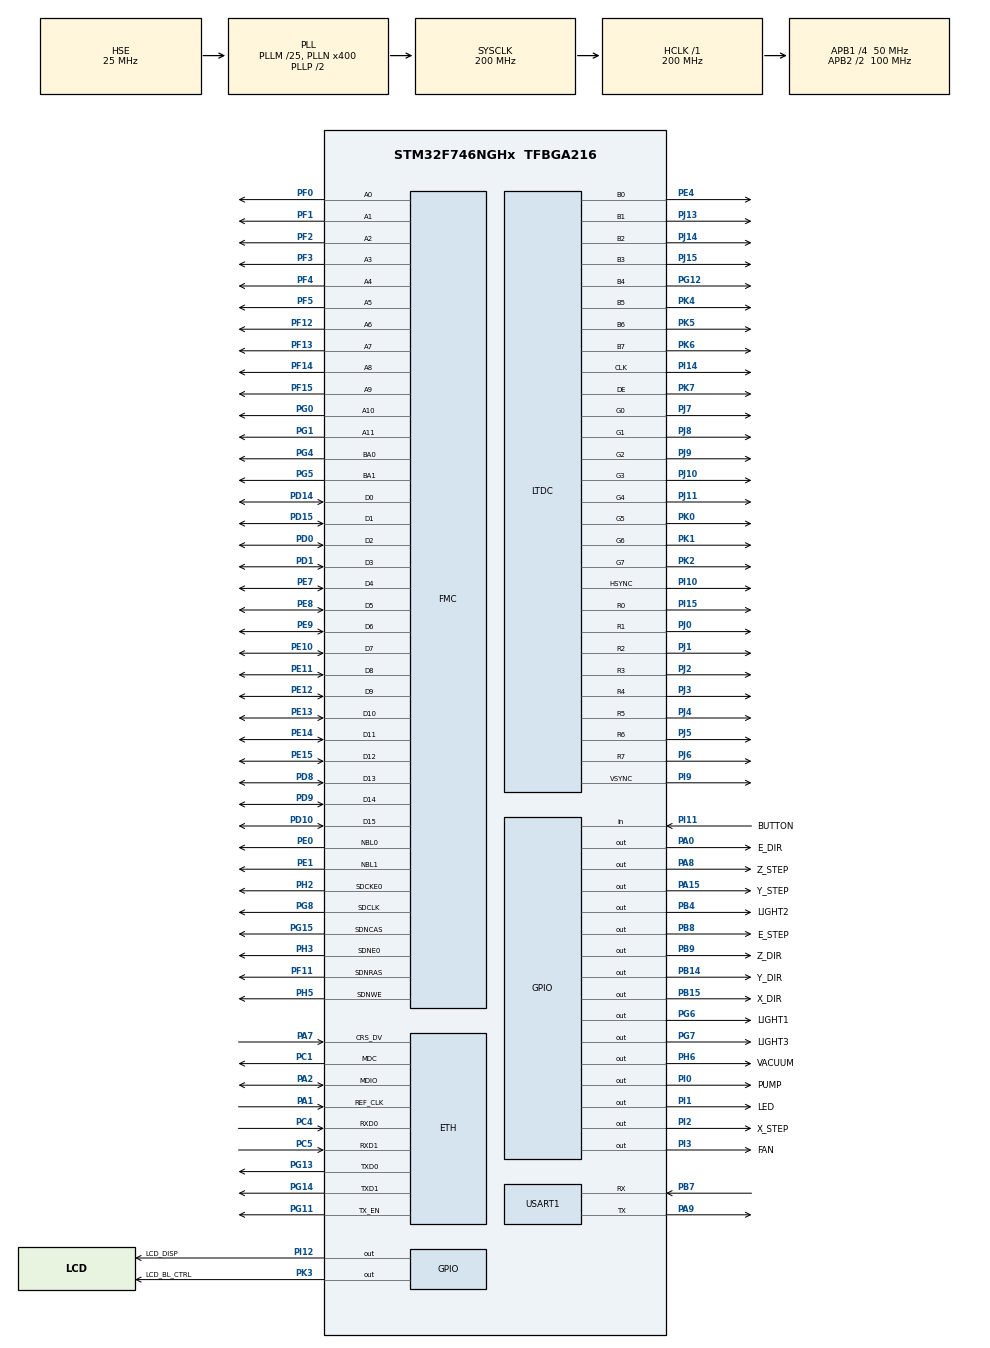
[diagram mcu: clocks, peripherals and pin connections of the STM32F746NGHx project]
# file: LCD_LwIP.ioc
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ETH.MACAddr=00\:80\:E1\:00\:00\:44
ETH.MediaInterface=ETH_MEDIA_INTERFACE_RMII
ETH.PhyAddress=0
LTDC.ActiveH=272
LTDC.ActiveW=480
LTDC.Alpha_L0=255
LTDC.Alpha_L1=255
LTDC.BlendingFactor1_L0=LTDC_BLENDING_FACTOR1_PAxCA
LTDC.BlendingFactor1_L1=LTDC_BLENDING_FACTOR1_PAxCA
LTDC.BlendingFactor2_L0=LTDC_BLENDING_FACTOR2_PAxCA
LTDC.BlendingFactor2_L1=LTDC_BLENDING_FACTOR2_PAxCA
LTDC.Green=255
LTDC.HBP=13
LTDC.HFP=32
LTDC.HSync=41
LTDC.ImageHeight_L0=272
LTDC.ImageHeight_L1=272
LTDC.ImageWidth_L0=480
LTDC.ImageWidth_L1=480
LTDC.PixelFormat_L0=LTDC_PIXEL_FORMAT_ARGB1555
LTDC.PixelFormat_L1=LTDC_PIXEL_FORMAT_ARGB1555
LTDC.VSync=10
LTDC.WindowX1_L0=480
LTDC.WindowX1_L1=480
LTDC.WindowY1_L0=272
LTDC.WindowY1_L1=272
LWIP.IP_ADDRESS=192.168.001.069
LWIP.LWIP_DHCP=0
LWIP.NETMASK_ADDRESS=255.255.255.000
LWIP.Version=v2.1.2_Cube
Mcu.Family=STM32F7
Mcu.Name=STM32F746NGHx
Mcu.Package=TFBGA216
NVIC.PriorityGroup=NVIC_PRIORITYGROUP_4
NVIC.TIM2_IRQn=true\:0\:0\:false\:false\:true\:true\:true
NVIC.TIM4_IRQn=true\:0\:0\:false\:false\:true\:true\:true
PA0/WKUP.GPIO_Label=E_DIR
PA0/WKUP.Signal=GPIO_Output
PA1.Mode=RMII
PA1.Signal=ETH_REF_CLK
PA15.GPIO_Label=Y_STEP
PA15.Signal=GPIO_Output
PA2.Mode=RMII
PA2.Signal=ETH_MDIO
PA7.Mode=RMII
PA7.Signal=ETH_CRS_DV
PA8.GPIO_Label=Z_STEP
PA8.Signal=GPIO_Output
PA9.Mode=Asynchronous
PA9.Signal=USART1_TX
PB14.GPIO_Label=Y_DIR
PB14.Signal=GPIO_Output
PB15.GPIO_Label=X_DIR
PB15.Signal=GPIO_Output
PB4.GPIO_Label=LIGHT2
PB4.Signal=GPIO_Output
PB7.Mode=Asynchronous
PB7.Signal=USART1_RX
PB8.GPIO_Label=E_STEP
PB8.Signal=GPIO_Output
PB9.GPIO_Label=Z_DIR
PB9.Signal=GPIO_Output
PC1.Mode=RMII
PC1.Signal=ETH_MDC
PC14/OSC32_IN.Mode=LSE-External-Oscillator
PC14/OSC32_IN.Signal=RCC_OSC32_IN
PC15/OSC32_OUT.Mode=LSE-External-Oscillator
PC15/OSC32_OUT.Signal=RCC_OSC32_OUT
PC4.Mode=RMII
PC4.Signal=ETH_RXD0
PC5.Mode=RMII
PC5.Signal=ETH_RXD1
PD0.Signal=FMC_D2_DA2
PD1.Signal=FMC_D3_DA3
PD10.Signal=FMC_D15_DA15
PD14.Signal=FMC_D0_DA0
PD15.Signal=FMC_D1_DA1
PD8.Signal=FMC_D13_DA13
PD9.Signal=FMC_D14_DA14
PE0.Signal=FMC_NBL0
PE1.Signal=FMC_NBL1
PE10.Signal=FMC_D7_DA7
PE11.Signal=FMC_D8_DA8
PE12.Signal=FMC_D9_DA9
PE13.Signal=FMC_D10_DA10
PE14.Signal=FMC_D11_DA11
PE15.Signal=FMC_D12_DA12
PE4.Mode=RGB888
PE4.Signal=LTDC_B0
PE7.Signal=FMC_D4_DA4
PE8.Signal=FMC_D5_DA5
PE9.Signal=FMC_D6_DA6
PF0.Signal=FMC_A0
PF1.Signal=FMC_A1
PF11.Signal=FMC_SDNRAS
PF12.Signal=FMC_A6
PF13.Signal=FMC_A7
PF14.Signal=FMC_A8
PF15.Signal=FMC_A9
PF2.Signal=FMC_A2
PF3.Signal=FMC_A3
PF4.Signal=FMC_A4
PF5.Signal=FMC_A5
PG0.Signal=FMC_A10
PG1.Signal=FMC_A11
PG11.Mode=RMII
PG11.Signal=ETH_TX_EN
PG12.Mode=RGB888
PG12.Signal=LTDC_B4
PG13.Mode=RMII
PG13.Signal=ETH_TXD0
PG14.Mode=RMII
PG14.Signal=ETH_TXD1
PG15.Signal=FMC_SDNCAS
PG4.Signal=FMC_A14_BA0
PG5.Signal=FMC_A15_BA1
PG6.GPIO_Label=LIGHT1
PG6.Signal=GPIO_Output
PG7.GPIO_Label=LIGHT3
PG7.Signal=GPIO_Output
PG8.Signal=FMC_SDCLK
PH0/OSC_IN.Mode=HSE-External-Oscillator
PH0/OSC_IN.Signal=RCC_OSC_IN
PH1/OSC_OUT.Mode=HSE-External-Oscillator
PH1/OSC_OUT.Signal=RCC_OSC_OUT
PH2.Mode=SdramChipSelect1_1
PH2.Signal=FMC_SDCKE0
PH3.Mode=SdramChipSelect1_1
PH3.Signal=FMC_SDNE0
PH5.Signal=FMC_SDNWE
PH6.GPIO_Label=VACUUM
PH6.Signal=GPIO_Output
PI0.GPIO_Label=PUMP
PI0.Signal=GPIO_Output
PI1.GPIO_Label=LED
PI1.Signal=GPIO_Output
PI10.Mode=RGB888
PI10.Signal=LTDC_HSYNC
PI11.GPIO_Label=BUTTON
PI11.Signal=GPIO_Input
PI12.GPIO_Label=LCD_DISP
PI12.Signal=GPIO_Output
PI14.Mode=RGB888
PI14.Signal=LTDC_CLK
PI15.Mode=RGB888
PI15.Signal=LTDC_R0
PI2.GPIO_Label=X_STEP
PI2.Signal=GPIO_Output
PI3.GPIO_Label=FAN
PI3.Signal=GPIO_Output
PI9.Mode=RGB888
PI9.Signal=LTDC_VSYNC
PJ0.Mode=RGB888
PJ0.Signal=LTDC_R1
PJ1.Mode=RGB888
PJ1.Signal=LTDC_R2
PJ10.Mode=RGB888
PJ10.Signal=LTDC_G3
PJ11.Mode=RGB888
PJ11.Signal=LTDC_G4
PJ13.Mode=RGB888
PJ13.Signal=LTDC_B1
PJ14.Mode=RGB888
PJ14.Signal=LTDC_B2
PJ15.Mode=RGB888
PJ15.Signal=LTDC_B3
PJ2.Mode=RGB888
PJ2.Signal=LTDC_R3
PJ3.Mode=RGB888
PJ3.Signal=LTDC_R4
PJ4.Mode=RGB888
PJ4.Signal=LTDC_R5
PJ5.Mode=RGB888
PJ5.Signal=LTDC_R6
PJ6.Mode=RGB888
PJ6.Signal=LTDC_R7
PJ7.Mode=RGB888
PJ7.Signal=LTDC_G0
PJ8.Mode=RGB888
PJ8.Signal=LTDC_G1
PJ9.Mode=RGB888
PJ9.Signal=LTDC_G2
PK0.Mode=RGB888
PK0.Signal=LTDC_G5
PK1.Mode=RGB888
PK1.Signal=LTDC_G6
PK2.Mode=RGB888
PK2.Signal=LTDC_G7
PK3.GPIO_Label=LCD_BL_CTRL
PK3.Signal=GPIO_Output
PK4.Mode=RGB888
PK4.Signal=LTDC_B5
PK5.Mode=RGB888
PK5.Signal=LTDC_B6
PK6.Mode=RGB888
PK6.Signal=LTDC_B7
PK7.Mode=RGB888
PK7.Signal=LTDC_DE
ProjectManager.HeapSize=0x200
ProjectManager.StackSize=0x400
ProjectManager.TargetToolchain=SW4STM32
RCC.AHBFreq_Value=200000000
RCC.APB1CLKDivider=RCC_HCLK_DIV4
RCC.APB1Freq_Value=50000000
RCC.APB1TimFreq_Value=100000000
RCC.APB2CLKDivider=RCC_HCLK_DIV2
RCC.APB2Freq_Value=100000000
RCC.APB2TimFreq_Value=200000000
RCC.CortexFreq_Value=200000000
RCC.HCLKFreq_Value=200000000
RCC.HSE_VALUE=25000000
RCC.HSI_VALUE=16000000
RCC.PLLM=25
RCC.PLLN=400
RCC.PLLSAIR=5
RCC.PLLSAIRDiv=RCC_PLLSAIDIVR_4
RCC.PLLSourceVirtual=RCC_PLLSOURCE_HSE
RCC.SYSCLKFreq_VALUE=200000000
RCC.SYSCLKSource=RCC_SYSCLKSOURCE_PLLCLK
RCC.USBFreq_Value=200000000
RCC.VCOOutputFreq_Value=400000000
SH.FMC_A0.0=FMC_A0,12b-sda1
SH.FMC_A1.0=FMC_A1,12b-sda1
SH.FMC_A10.0=FMC_A10,12b-sda1
SH.FMC_A11.0=FMC_A11,12b-sda1
SH.FMC_A14_BA0.0=FMC_BA0,FourSdramBanks1
SH.FMC_A15_BA1.0=FMC_BA1,FourSdramBanks1
SH.FMC_A2.0=FMC_A2,12b-sda1
SH.FMC_A3.0=FMC_A3,12b-sda1
SH.FMC_A4.0=FMC_A4,12b-sda1
SH.FMC_A5.0=FMC_A5,12b-sda1
SH.FMC_A6.0=FMC_A6,12b-sda1
SH.FMC_A7.0=FMC_A7,12b-sda1
SH.FMC_A8.0=FMC_A8,12b-sda1
SH.FMC_A9.0=FMC_A9,12b-sda1
SH.FMC_D0_DA0.0=FMC_D0,sd-16b-d1
SH.FMC_D10_DA10.0=FMC_D10,sd-16b-d1
SH.FMC_D11_DA11.0=FMC_D11,sd-16b-d1
SH.FMC_D12_DA12.0=FMC_D12,sd-16b-d1
SH.FMC_D13_DA13.0=FMC_D13,sd-16b-d1
SH.FMC_D14_DA14.0=FMC_D14,sd-16b-d1
SH.FMC_D15_DA15.0=FMC_D15,sd-16b-d1
SH.FMC_D1_DA1.0=FMC_D1,sd-16b-d1
SH.FMC_D2_DA2.0=FMC_D2,sd-16b-d1
SH.FMC_D3_DA3.0=FMC_D3,sd-16b-d1
SH.FMC_D4_DA4.0=FMC_D4,sd-16b-d1
SH.FMC_D5_DA5.0=FMC_D5,sd-16b-d1
SH.FMC_D6_DA6.0=FMC_D6,sd-16b-d1
SH.FMC_D7_DA7.0=FMC_D7,sd-16b-d1
SH.FMC_D8_DA8.0=FMC_D8,sd-16b-d1
SH.FMC_D9_DA9.0=FMC_D9,sd-16b-d1
SH.FMC_NBL0.0=FMC_NBL0,Sd2ByteEnable1
SH.FMC_NBL1.0=FMC_NBL1,Sd2ByteEnable1
SH.FMC_SDCLK.0=FMC_SDCLK,12b-sda1
SH.FMC_SDNCAS.0=FMC_SDNCAS,12b-sda1
SH.FMC_SDNRAS.0=FMC_SDNRAS,12b-sda1
SH.FMC_SDNWE.0=FMC_SDNWE,12b-sda1
TIM2.AutoReloadPreload=TIM_AUTORELOAD_PRELOAD_ENABLE
TIM2.Period=25000-1
TIM2.Prescaler=200
TIM4.AutoReloadPreload=TIM_AUTORELOAD_PRELOAD_ENABLE
TIM4.Channel-PWM\ Generation1\ No\ Output=TIM_CHANNEL_1
TIM4.Channel-PWM\ Generation2\ No\ Output=TIM_CHANNEL_2
TIM4.Channel-PWM\ Generation3\ No\ Output=TIM_CHANNEL_3
TIM4.Channel-PWM\ Generation4\ No\ Output=TIM_CHANNEL_4
TIM4.Period=10-1
TIM4.Prescaler=200
USART1.VirtualMode=VM_ASYNC
USART1.VirtualMode-Asynchronous=VM_ASYNC
USART1.WordLength=WORDLENGTH_8B
VP_DMA2D_VS_DMA2D.Mode=DMA2D_Activate
VP_LWIP_VS_Enabled.Mode=Enabled
VP_TIM2_VS_ClockSourceINT.Mode=Internal
VP_TIM4_VS_ClockSourceINT.Mode=Internal
VP_TIM4_VS_no_output1.Mode=PWM Generation1 No Output
VP_TIM4_VS_no_output2.Mode=PWM Generation2 No Output
VP_TIM4_VS_no_output3.Mode=PWM Generation3 No Output
VP_TIM4_VS_no_output4.Mode=PWM Generation4 No Output
board=STM32F746G-DISCO

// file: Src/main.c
/* USER CODE BEGIN Header */
/**
  ******************************************************************************
  * @file           : main.c
  * @brief          : Main program body
  ******************************************************************************
  * @attention
  *
  * <h2><center>&copy; Copyright (c) 2020 STMicroelectronics.
  * All rights reserved.</center></h2>
  *
  * This software component is licensed by ST under Ultimate Liberty license
  * SLA0044, the "License"; You may not use this file except in compliance with
  * the License. You may obtain a copy of the License at:
  *                             www.st.com/SLA0044
  *
  ******************************************************************************
  */
/* USER CODE END Header */
#include "main.h"
#include "lwip.h"

/* USER CODE BEGIN Includes */
#include <stdio.h>
#include <stdint.h>
#include <stdbool.h>
#include <string.h>

#include "stm32746g_discovery.h"
#include "stm32746g_discovery_lcd.h"
#include "stm32746g_discovery_sdram.h"
#include "stm32746g_discovery_ts.h"

#include "coms.h"
#include "logo_data.h"
#include "buttons.h"
#include "gcode.h"
#include "actuators.h"
#include "motion.h"

/* USER CODE END Includes */

DMA2D_HandleTypeDef hdma2d;

LTDC_HandleTypeDef hltdc;

TIM_HandleTypeDef htim2;
TIM_HandleTypeDef htim4;

UART_HandleTypeDef huart1;

SDRAM_HandleTypeDef hsdram1;

/* USER CODE BEGIN PV */
/* Private variables ---------------------------------------------------------*/

/* Lcd text */
static const char *pcHeading1 = "Current command:";
static const char *pcHeading2 = "Current position:";
static const char *pcButton1Text = "Pump:";
static const char *pcLightText = "Light:";
static const char *pcVacuumText = "Vacuum:";

/* button handles */
static ButnStateTypeDef *pxPumpButton = NULL;
static ButnStateTypeDef *pxLightButton = NULL;
static ButnStateTypeDef *pxVacuumButton = NULL;

/* coordinates */
static GcodeCoordinateTypeDef xCurrentPosition = {0.0,0.0,0.0,0.0};

/* USER CODE END PV */

void SystemClock_Config(void);
static void MX_GPIO_Init(void);
static void MX_LTDC_Init(void);
static void MX_USART1_UART_Init(void);
static void MX_DMA2D_Init(void);
static void MX_FMC_Init(void);
static void MX_TIM2_Init(void);
static void MX_TIM4_Init(void);
/* USER CODE BEGIN PFP */
/* Private function prototypes -----------------------------------------------*/

void vMainNewDataCallback( char* pcNewCommand );
void vMainNewClientCallback( char *pcRemoteIP );
void vMainConnectionCloseCallback( void );

/* USER CODE END PFP */

/* USER CODE BEGIN 0 */
#include <errno.h>
#include <sys/stat.h>
#include <sys/times.h>
#include <sys/unistd.h>

int _write(int file, char *ptr, int len) {
    HAL_StatusTypeDef xStatus;
    switch (file) {
    case STDOUT_FILENO: /*stdout*/
		xStatus = HAL_UART_Transmit(&huart1, (uint8_t*)ptr, len, HAL_MAX_DELAY);
		if (xStatus != HAL_OK) {
			errno = EIO;
			return -1;
		}
        break;
    case STDERR_FILENO: /* stderr */
		xStatus = HAL_UART_Transmit(&huart1, (uint8_t*)ptr, len, HAL_MAX_DELAY);
		if (xStatus != HAL_OK) {
			errno = EIO;
			return -1;
		}
        break;
    default:
        errno = EBADF;
        return -1;
    }
    return len;
}
/* USER CODE END 0 */

int main(void)
{

  /* MCU Configuration--------------------------------------------------------*/

  /* Reset of all peripherals, Initializes the Flash interface and the Systick. */
  HAL_Init();

  /* Configure the system clock */
  SystemClock_Config();

  /* Initialize all configured peripherals */
  MX_GPIO_Init();
  MX_LTDC_Init();
  MX_USART1_UART_Init();
  MX_DMA2D_Init();
  MX_FMC_Init();
  MX_LWIP_Init();
  MX_TIM2_Init();
  MX_TIM4_Init();
  /* USER CODE BEGIN 2 */

  /* LCD Initialization */
    BSP_LCD_Init();
    //Init the display controller layers (0 and 1)
    BSP_LCD_LayerDefaultInit( 1, LCD_FB_START_ADDRESS );
    //start address of frame buffer 0 = display size * (4bytes/pixel) further in memory
    BSP_LCD_LayerDefaultInit( 0, LCD_FB_START_ADDRESS+(480*272*4) );

    /* Enable the LCD */
    BSP_LCD_DisplayOn();

    /* Select the LCD Background Layer  */
    BSP_LCD_SelectLayer( 0 );
    /* Clear the Background Layer */
    BSP_LCD_Clear( LCD_COLOR_WHITE );

    /* Select the front layer */
    BSP_LCD_SelectLayer( 1 );
    /* Clear the foreground Layer */
    BSP_LCD_Clear( LCD_COLOR_WHITE );

    /* Display the logo */
    WDA_LCD_DrawBitmap( LOGO_DATA, 10, 5, LOGO_DATA_X_PIXEL, LOGO_DATA_Y_PIXEL, LOGO_DATA_FORMAT );

    /* Display the headers */
    BSP_LCD_SetFont( &Font20 );
    BSP_LCD_SetTextColor( LCD_COLOR_BLUE );
    BSP_LCD_DisplayStringAt( 10, LOGO_DATA_Y_PIXEL + 10, (uint8_t*)pcHeading1, LEFT_MODE );
    BSP_LCD_DisplayStringAtLine( 6, (uint8_t*)pcHeading2 );

    /* Display buttons */
    BSP_LCD_DisplayStringAt( 10, 215, (uint8_t*)pcButton1Text, LEFT_MODE );
    pxPumpButton = pxButtonsNewButton();			//new button
    vButtonsSetPosition( pxPumpButton, 83, 210 );	//position on screen
    vButtonsDraw( pxPumpButton );					//draw
    vActuatorsSetButtonHandler( pxPumpButton, ACTUATORS_PUMPEVENT );

    BSP_LCD_DisplayStringAt( 150, 215, (uint8_t*)pcLightText, LEFT_MODE );
    pxLightButton = pxButtonsNewButton();			//new button
    vButtonsSetPosition( pxLightButton, 233, 210 );	//position on screen
    vButtonsDraw( pxLightButton );					//draw
    vActuatorsSetButtonHandler( pxLightButton, ACTUATORS_LIGHTEVENT );

    BSP_LCD_DisplayStringAt( 305, 215, (uint8_t*)pcVacuumText, LEFT_MODE );
    pxVacuumButton = pxButtonsNewButton();			//new button
    vButtonsSetPosition( pxVacuumButton, 397, 210 );//position on screen
    vButtonsDraw( pxVacuumButton );					//draw
    vActuatorsSetButtonHandler( pxVacuumButton, ACTUATORS_VACUUMEVENT );

    /* Set the font and color for later */
    BSP_LCD_SetFont( &Font16 );
    BSP_LCD_SetTextColor( LCD_COLOR_BLACK );

    /* Initialize touch */
    BSP_TS_Init( BSP_LCD_GetXSize(), BSP_LCD_GetYSize());

    /* Initialize periodic timer2 */
    HAL_TIM_Base_Start_IT( &htim2 ),

    /* Set the callback functions */
    vComsSetNewCommandCallback( vMainNewDataCallback );
    vComsSetNewClientCallback( vMainNewClientCallback );
    vComsSetConnectionClosedCallback( vMainConnectionCloseCallback );

    /* Initialize the communication */
    vComsInitListener();

  /* USER CODE END 2 */

  /* Infinite loop */
  while (1)
  {

    /* USER CODE BEGIN 3 */
	  /* Handle lwip */
	  MX_LWIP_Process();
  }
  /* USER CODE END 3 */
}

void SystemClock_Config(void)
{
  RCC_OscInitTypeDef RCC_OscInitStruct = {0};
  RCC_ClkInitTypeDef RCC_ClkInitStruct = {0};
  RCC_PeriphCLKInitTypeDef PeriphClkInitStruct = {0};

  /** Configure LSE Drive Capability
  */
  HAL_PWR_EnableBkUpAccess();
  /** Configure the main internal regulator output voltage
  */
  __HAL_RCC_PWR_CLK_ENABLE();
  __HAL_PWR_VOLTAGESCALING_CONFIG(PWR_REGULATOR_VOLTAGE_SCALE1);
  /** Initializes the RCC Oscillators according to the specified parameters
  * in the RCC_OscInitTypeDef structure.
  */
  RCC_OscInitStruct.OscillatorType = RCC_OSCILLATORTYPE_HSE;
  RCC_OscInitStruct.HSEState = RCC_HSE_ON;
  RCC_OscInitStruct.PLL.PLLState = RCC_PLL_ON;
  RCC_OscInitStruct.PLL.PLLSource = RCC_PLLSOURCE_HSE;
  RCC_OscInitStruct.PLL.PLLM = 25;
  RCC_OscInitStruct.PLL.PLLN = 400;
  RCC_OscInitStruct.PLL.PLLP = RCC_PLLP_DIV2;
  RCC_OscInitStruct.PLL.PLLQ = 2;
  if (HAL_RCC_OscConfig(&RCC_OscInitStruct) != HAL_OK)
  {
    Error_Handler();
  }
  /** Activate the Over-Drive mode
  */
  if (HAL_PWREx_EnableOverDrive() != HAL_OK)
  {
    Error_Handler();
  }
  /** Initializes the CPU, AHB and APB buses clocks
  */
  RCC_ClkInitStruct.ClockType = RCC_CLOCKTYPE_HCLK|RCC_CLOCKTYPE_SYSCLK
                              |RCC_CLOCKTYPE_PCLK1|RCC_CLOCKTYPE_PCLK2;
  RCC_ClkInitStruct.SYSCLKSource = RCC_SYSCLKSOURCE_PLLCLK;
  RCC_ClkInitStruct.AHBCLKDivider = RCC_SYSCLK_DIV1;
  RCC_ClkInitStruct.APB1CLKDivider = RCC_HCLK_DIV4;
  RCC_ClkInitStruct.APB2CLKDivider = RCC_HCLK_DIV2;

  if (HAL_RCC_ClockConfig(&RCC_ClkInitStruct, FLASH_LATENCY_6) != HAL_OK)
  {
    Error_Handler();
  }
  PeriphClkInitStruct.PeriphClockSelection = RCC_PERIPHCLK_LTDC|RCC_PERIPHCLK_USART1;
  PeriphClkInitStruct.PLLSAI.PLLSAIN = 192;
  PeriphClkInitStruct.PLLSAI.PLLSAIR = 5;
  PeriphClkInitStruct.PLLSAI.PLLSAIQ = 2;
  PeriphClkInitStruct.PLLSAI.PLLSAIP = RCC_PLLSAIP_DIV2;
  PeriphClkInitStruct.PLLSAIDivQ = 1;
  PeriphClkInitStruct.PLLSAIDivR = RCC_PLLSAIDIVR_4;
  PeriphClkInitStruct.Usart1ClockSelection = RCC_USART1CLKSOURCE_PCLK2;
  if (HAL_RCCEx_PeriphCLKConfig(&PeriphClkInitStruct) != HAL_OK)
  {
    Error_Handler();
  }
}

static void MX_DMA2D_Init(void)
{

  hdma2d.Instance = DMA2D;
  hdma2d.Init.Mode = DMA2D_M2M;
  hdma2d.Init.ColorMode = DMA2D_OUTPUT_ARGB8888;
  hdma2d.Init.OutputOffset = 0;
  hdma2d.LayerCfg[1].InputOffset = 0;
  hdma2d.LayerCfg[1].InputColorMode = DMA2D_INPUT_ARGB8888;
  hdma2d.LayerCfg[1].AlphaMode = DMA2D_NO_MODIF_ALPHA;
  hdma2d.LayerCfg[1].InputAlpha = 0;
  if (HAL_DMA2D_Init(&hdma2d) != HAL_OK)
  {
    Error_Handler();
  }
  if (HAL_DMA2D_ConfigLayer(&hdma2d, 1) != HAL_OK)
  {
    Error_Handler();
  }

}

static void MX_LTDC_Init(void)
{

  LTDC_LayerCfgTypeDef pLayerCfg = {0};
  LTDC_LayerCfgTypeDef pLayerCfg1 = {0};

  hltdc.Instance = LTDC;
  hltdc.Init.HSPolarity = LTDC_HSPOLARITY_AL;
  hltdc.Init.VSPolarity = LTDC_VSPOLARITY_AL;
  hltdc.Init.DEPolarity = LTDC_DEPOLARITY_AL;
  hltdc.Init.PCPolarity = LTDC_PCPOLARITY_IPC;
  hltdc.Init.HorizontalSync = 40;
  hltdc.Init.VerticalSync = 9;
  hltdc.Init.AccumulatedHBP = 53;
  hltdc.Init.AccumulatedVBP = 11;
  hltdc.Init.AccumulatedActiveW = 533;
  hltdc.Init.AccumulatedActiveH = 283;
  hltdc.Init.TotalWidth = 565;
  hltdc.Init.TotalHeigh = 285;
  hltdc.Init.Backcolor.Blue = 0;
  hltdc.Init.Backcolor.Green = 255;
  hltdc.Init.Backcolor.Red = 0;
  if (HAL_LTDC_Init(&hltdc) != HAL_OK)
  {
    Error_Handler();
  }
  pLayerCfg.WindowX0 = 0;
  pLayerCfg.WindowX1 = 480;
  pLayerCfg.WindowY0 = 0;
  pLayerCfg.WindowY1 = 272;
  pLayerCfg.PixelFormat = LTDC_PIXEL_FORMAT_ARGB1555;
  pLayerCfg.Alpha = 255;
  pLayerCfg.Alpha0 = 0;
  pLayerCfg.BlendingFactor1 = LTDC_BLENDING_FACTOR1_PAxCA;
  pLayerCfg.BlendingFactor2 = LTDC_BLENDING_FACTOR2_PAxCA;
  pLayerCfg.FBStartAdress = 0;
  pLayerCfg.ImageWidth = 480;
  pLayerCfg.ImageHeight = 272;
  pLayerCfg.Backcolor.Blue = 0;
  pLayerCfg.Backcolor.Green = 0;
  pLayerCfg.Backcolor.Red = 0;
  if (HAL_LTDC_ConfigLayer(&hltdc, &pLayerCfg, 0) != HAL_OK)
  {
    Error_Handler();
  }
  pLayerCfg1.WindowX0 = 0;
  pLayerCfg1.WindowX1 = 480;
  pLayerCfg1.WindowY0 = 0;
  pLayerCfg1.WindowY1 = 272;
  pLayerCfg1.PixelFormat = LTDC_PIXEL_FORMAT_ARGB1555;
  pLayerCfg1.Alpha = 255;
  pLayerCfg1.Alpha0 = 0;
  pLayerCfg1.BlendingFactor1 = LTDC_BLENDING_FACTOR1_PAxCA;
  pLayerCfg1.BlendingFactor2 = LTDC_BLENDING_FACTOR2_PAxCA;
  pLayerCfg1.FBStartAdress = 0;
  pLayerCfg1.ImageWidth = 480;
  pLayerCfg1.ImageHeight = 272;
  pLayerCfg1.Backcolor.Blue = 0;
  pLayerCfg1.Backcolor.Green = 0;
  pLayerCfg1.Backcolor.Red = 0;
  if (HAL_LTDC_ConfigLayer(&hltdc, &pLayerCfg1, 1) != HAL_OK)
  {
    Error_Handler();
  }

}

static void MX_TIM2_Init(void)
{

  TIM_ClockConfigTypeDef sClockSourceConfig = {0};
  TIM_MasterConfigTypeDef sMasterConfig = {0};

  htim2.Instance = TIM2;
  htim2.Init.Prescaler = 200;
  htim2.Init.CounterMode = TIM_COUNTERMODE_UP;
  htim2.Init.Period = 25000-1;
  htim2.Init.ClockDivision = TIM_CLOCKDIVISION_DIV1;
  htim2.Init.AutoReloadPreload = TIM_AUTORELOAD_PRELOAD_ENABLE;
  if (HAL_TIM_Base_Init(&htim2) != HAL_OK)
  {
    Error_Handler();
  }
  sClockSourceConfig.ClockSource = TIM_CLOCKSOURCE_INTERNAL;
  if (HAL_TIM_ConfigClockSource(&htim2, &sClockSourceConfig) != HAL_OK)
  {
    Error_Handler();
  }
  sMasterConfig.MasterOutputTrigger = TIM_TRGO_RESET;
  sMasterConfig.MasterSlaveMode = TIM_MASTERSLAVEMODE_DISABLE;
  if (HAL_TIMEx_MasterConfigSynchronization(&htim2, &sMasterConfig) != HAL_OK)
  {
    Error_Handler();
  }

}

static void MX_TIM4_Init(void)
{

  TIM_ClockConfigTypeDef sClockSourceConfig = {0};
  TIM_MasterConfigTypeDef sMasterConfig = {0};
  TIM_OC_InitTypeDef sConfigOC = {0};

  htim4.Instance = TIM4;
  htim4.Init.Prescaler = 200;
  htim4.Init.CounterMode = TIM_COUNTERMODE_UP;
  htim4.Init.Period = 10-1;
  htim4.Init.ClockDivision = TIM_CLOCKDIVISION_DIV1;
  htim4.Init.AutoReloadPreload = TIM_AUTORELOAD_PRELOAD_ENABLE;
  if (HAL_TIM_Base_Init(&htim4) != HAL_OK)
  {
    Error_Handler();
  }
  sClockSourceConfig.ClockSource = TIM_CLOCKSOURCE_INTERNAL;
  if (HAL_TIM_ConfigClockSource(&htim4, &sClockSourceConfig) != HAL_OK)
  {
    Error_Handler();
  }
  if (HAL_TIM_PWM_Init(&htim4) != HAL_OK)
  {
    Error_Handler();
  }
  sMasterConfig.MasterOutputTrigger = TIM_TRGO_RESET;
  sMasterConfig.MasterSlaveMode = TIM_MASTERSLAVEMODE_DISABLE;
  if (HAL_TIMEx_MasterConfigSynchronization(&htim4, &sMasterConfig) != HAL_OK)
  {
    Error_Handler();
  }
  sConfigOC.OCMode = TIM_OCMODE_PWM1;
  sConfigOC.Pulse = 0;
  sConfigOC.OCPolarity = TIM_OCPOLARITY_HIGH;
  sConfigOC.OCFastMode = TIM_OCFAST_DISABLE;
  if (HAL_TIM_PWM_ConfigChannel(&htim4, &sConfigOC, TIM_CHANNEL_1) != HAL_OK)
  {
    Error_Handler();
  }
  if (HAL_TIM_PWM_ConfigChannel(&htim4, &sConfigOC, TIM_CHANNEL_2) != HAL_OK)
  {
    Error_Handler();
  }
  if (HAL_TIM_PWM_ConfigChannel(&htim4, &sConfigOC, TIM_CHANNEL_3) != HAL_OK)
  {
    Error_Handler();
  }
  if (HAL_TIM_PWM_ConfigChannel(&htim4, &sConfigOC, TIM_CHANNEL_4) != HAL_OK)
  {
    Error_Handler();
  }

}

static void MX_USART1_UART_Init(void)
{

  huart1.Instance = USART1;
  huart1.Init.BaudRate = 115200;
  huart1.Init.WordLength = UART_WORDLENGTH_8B;
  huart1.Init.StopBits = UART_STOPBITS_1;
  huart1.Init.Parity = UART_PARITY_NONE;
  huart1.Init.Mode = UART_MODE_TX_RX;
  huart1.Init.HwFlowCtl = UART_HWCONTROL_NONE;
  huart1.Init.OverSampling = UART_OVERSAMPLING_16;
  huart1.Init.OneBitSampling = UART_ONE_BIT_SAMPLE_DISABLE;
  huart1.AdvancedInit.AdvFeatureInit = UART_ADVFEATURE_NO_INIT;
  if (HAL_UART_Init(&huart1) != HAL_OK)
  {
    Error_Handler();
  }

}

/* FMC initialization function */
static void MX_FMC_Init(void)
{

  FMC_SDRAM_TimingTypeDef SdramTiming = {0};

  /** Perform the SDRAM1 memory initialization sequence
  */
  hsdram1.Instance = FMC_SDRAM_DEVICE;
  /* hsdram1.Init */
  hsdram1.Init.SDBank = FMC_SDRAM_BANK1;
  hsdram1.Init.ColumnBitsNumber = FMC_SDRAM_COLUMN_BITS_NUM_8;
  hsdram1.Init.RowBitsNumber = FMC_SDRAM_ROW_BITS_NUM_12;
  hsdram1.Init.MemoryDataWidth = FMC_SDRAM_MEM_BUS_WIDTH_16;
  hsdram1.Init.InternalBankNumber = FMC_SDRAM_INTERN_BANKS_NUM_4;
  hsdram1.Init.CASLatency = FMC_SDRAM_CAS_LATENCY_1;
  hsdram1.Init.WriteProtection = FMC_SDRAM_WRITE_PROTECTION_DISABLE;
  hsdram1.Init.SDClockPeriod = FMC_SDRAM_CLOCK_DISABLE;
  hsdram1.Init.ReadBurst = FMC_SDRAM_RBURST_DISABLE;
  hsdram1.Init.ReadPipeDelay = FMC_SDRAM_RPIPE_DELAY_0;
  /* SdramTiming */
  SdramTiming.LoadToActiveDelay = 16;
  SdramTiming.ExitSelfRefreshDelay = 16;
  SdramTiming.SelfRefreshTime = 16;
  SdramTiming.RowCycleDelay = 16;
  SdramTiming.WriteRecoveryTime = 16;
  SdramTiming.RPDelay = 16;
  SdramTiming.RCDDelay = 16;

  if (HAL_SDRAM_Init(&hsdram1, &SdramTiming) != HAL_OK)
  {
    Error_Handler( );
  }

}

static void MX_GPIO_Init(void)
{
  GPIO_InitTypeDef GPIO_InitStruct = {0};

  /* GPIO Ports Clock Enable */
  __HAL_RCC_GPIOE_CLK_ENABLE();
  __HAL_RCC_GPIOG_CLK_ENABLE();
  __HAL_RCC_GPIOB_CLK_ENABLE();
  __HAL_RCC_GPIOA_CLK_ENABLE();
  __HAL_RCC_GPIOJ_CLK_ENABLE();
  __HAL_RCC_GPIOD_CLK_ENABLE();
  __HAL_RCC_GPIOK_CLK_ENABLE();
  __HAL_RCC_GPIOI_CLK_ENABLE();
  __HAL_RCC_GPIOF_CLK_ENABLE();
  __HAL_RCC_GPIOC_CLK_ENABLE();
  __HAL_RCC_GPIOH_CLK_ENABLE();

  /*Configure GPIO pin Output Level */
  HAL_GPIO_WritePin(GPIOB, E_STEP_Pin|LIGHT2_Pin|Z_DIR_Pin|Y_DIR_Pin
                          |X_DIR_Pin, GPIO_PIN_RESET);

  /*Configure GPIO pin Output Level */
  HAL_GPIO_WritePin(GPIOA, Y_STEP_Pin|Z_STEP_Pin|E_DIR_Pin, GPIO_PIN_RESET);

  /*Configure GPIO pin Output Level */
  HAL_GPIO_WritePin(GPIOI, FAN_Pin|X_STEP_Pin|LED_Pin|LCD_DISP_Pin
                          |PUMP_Pin, GPIO_PIN_RESET);

  /*Configure GPIO pin Output Level */
  HAL_GPIO_WritePin(LCD_BL_CTRL_GPIO_Port, LCD_BL_CTRL_Pin, GPIO_PIN_RESET);

  /*Configure GPIO pin Output Level */
  HAL_GPIO_WritePin(GPIOG, LIGHT3_Pin|LIGHT1_Pin, GPIO_PIN_RESET);

  /*Configure GPIO pin Output Level */
  HAL_GPIO_WritePin(VACUUM_GPIO_Port, VACUUM_Pin, GPIO_PIN_RESET);

  /*Configure GPIO pins : E_STEP_Pin LIGHT2_Pin Z_DIR_Pin Y_DIR_Pin
                           X_DIR_Pin */
  GPIO_InitStruct.Pin = E_STEP_Pin|LIGHT2_Pin|Z_DIR_Pin|Y_DIR_Pin
                          |X_DIR_Pin;
  GPIO_InitStruct.Mode = GPIO_MODE_OUTPUT_PP;
  GPIO_InitStruct.Pull = GPIO_NOPULL;
  GPIO_InitStruct.Speed = GPIO_SPEED_FREQ_LOW;
  HAL_GPIO_Init(GPIOB, &GPIO_InitStruct);

  /*Configure GPIO pins : Y_STEP_Pin Z_STEP_Pin E_DIR_Pin */
  GPIO_InitStruct.Pin = Y_STEP_Pin|Z_STEP_Pin|E_DIR_Pin;
  GPIO_InitStruct.Mode = GPIO_MODE_OUTPUT_PP;
  GPIO_InitStruct.Pull = GPIO_NOPULL;
  GPIO_InitStruct.Speed = GPIO_SPEED_FREQ_LOW;
  HAL_GPIO_Init(GPIOA, &GPIO_InitStruct);

  /*Configure GPIO pins : FAN_Pin X_STEP_Pin LED_Pin LCD_DISP_Pin
                           PUMP_Pin */
  GPIO_InitStruct.Pin = FAN_Pin|X_STEP_Pin|LED_Pin|LCD_DISP_Pin
                          |PUMP_Pin;
  GPIO_InitStruct.Mode = GPIO_MODE_OUTPUT_PP;
  GPIO_InitStruct.Pull = GPIO_NOPULL;
  GPIO_InitStruct.Speed = GPIO_SPEED_FREQ_LOW;
  HAL_GPIO_Init(GPIOI, &GPIO_InitStruct);

  /*Configure GPIO pin : LCD_BL_CTRL_Pin */
  GPIO_InitStruct.Pin = LCD_BL_CTRL_Pin;
  GPIO_InitStruct.Mode = GPIO_MODE_OUTPUT_PP;
  GPIO_InitStruct.Pull = GPIO_NOPULL;
  GPIO_InitStruct.Speed = GPIO_SPEED_FREQ_LOW;
  HAL_GPIO_Init(LCD_BL_CTRL_GPIO_Port, &GPIO_InitStruct);

  /*Configure GPIO pin : BUTTON_Pin */
  GPIO_InitStruct.Pin = BUTTON_Pin;
  GPIO_InitStruct.Mode = GPIO_MODE_INPUT;
  GPIO_InitStruct.Pull = GPIO_NOPULL;
  HAL_GPIO_Init(BUTTON_GPIO_Port, &GPIO_InitStruct);

  /*Configure GPIO pins : LIGHT3_Pin LIGHT1_Pin */
  GPIO_InitStruct.Pin = LIGHT3_Pin|LIGHT1_Pin;
  GPIO_InitStruct.Mode = GPIO_MODE_OUTPUT_PP;
  GPIO_InitStruct.Pull = GPIO_NOPULL;
  GPIO_InitStruct.Speed = GPIO_SPEED_FREQ_LOW;
  HAL_GPIO_Init(GPIOG, &GPIO_InitStruct);

  /*Configure GPIO pin : VACUUM_Pin */
  GPIO_InitStruct.Pin = VACUUM_Pin;
  GPIO_InitStruct.Mode = GPIO_MODE_OUTPUT_PP;
  GPIO_InitStruct.Pull = GPIO_NOPULL;
  GPIO_InitStruct.Speed = GPIO_SPEED_FREQ_LOW;
  HAL_GPIO_Init(VACUUM_GPIO_Port, &GPIO_InitStruct);

}

/* USER CODE BEGIN 4 */
/*
 * called by coms when a new gcode command is received
 */
void vMainNewDataCallback( char* pcNewCommand )
{
/* gcode command */
GcodeCommandTypedef *pxCurrentCommand = NULL;

	/* Clear previous */
	BSP_LCD_ClearStringLine( 4 );
	BSP_LCD_ClearStringLine( 5 );

	/* Display command and comment */
	BSP_LCD_DisplayStringAtLine( 4, (uint8_t*)strtok( pcNewCommand, ";" ) );
	BSP_LCD_DisplayStringAtLine( 5, (uint8_t*)strtok( NULL, ";" ) );

	/* Extract G-Code */
	pxCurrentCommand = pxGcodeExtractCommand( pcNewCommand, xCurrentPosition );

	/* Actuate or move */
	if( pxCurrentCommand->type == GCODE_ACTUATE )
	{
		vActuatorsHandle( pxCurrentCommand->code );
	}
	else if( pxCurrentCommand->type == GCODE_POSITION)
	{
		/* linear move to command */
		if( ( pxCurrentCommand->code == 0 ) || ( pxCurrentCommand->code == 1 ) )
		{
			/* move to the requested coordinate */
			vMotionCalculateSteps( xCurrentPosition, pxCurrentCommand->position );
			vMotionStartMovement();

			/* set new coordinate after completion */
			vGcodeCopyCo( &xCurrentPosition, pxCurrentCommand->position );
		}
		/* home command */
		else if( pxCurrentCommand->code == 28 )
		{
			xCurrentPosition.x = 0.0;
			xCurrentPosition.y = 0.0;
			xCurrentPosition.z = 0.0;
			xCurrentPosition.e = 0.0;
		}
		else
		{
			printf( "code G%hu not implemented\r\n", pxCurrentCommand->code );
		}
	}
	else
	{
		printf( "****\r\nInvalid Command!\r\n****\r\n" );
	}

	vGcodeFree( pxCurrentCommand );	//free the allocated memory
}

/*
 * timer 2 every second
 */
void HAL_TIM_PeriodElapsedCallback( TIM_HandleTypeDef *htim )
{
char pcTempCoString[128] = "";
	if(htim == &htim2)
	{
		/* Handle button presses */
		if( bButtonsCheckTouch( pxPumpButton ) )
		{
			HAL_GPIO_TogglePin( PUMP_GPIO_Port, PUMP_Pin );
		}
		if( bButtonsCheckTouch( pxLightButton ) )
		{
			HAL_GPIO_TogglePin( LIGHT1_GPIO_Port, LIGHT1_Pin );
		}
		if( bButtonsCheckTouch( pxVacuumButton ) )
		{
			HAL_GPIO_TogglePin( VACUUM_GPIO_Port, VACUUM_Pin );
		}

		/* Redraw if state changed */
		vButtonsDraw( pxPumpButton );
		vButtonsDraw( pxLightButton );
		vButtonsDraw( pxVacuumButton );

		/* Construct coordinate string
		 * -u _printf_float must be added to linker flags
		 */
		sprintf( pcTempCoString, "X%.3f Y%.3f Z%.2f E%.2f", xCurrentPosition.x, xCurrentPosition.y, xCurrentPosition.z, xCurrentPosition.e );

		/* redraw coordinates */
		while( !( hltdc.Instance->CDSR & ( 1<<2 ) ) );	//wait for vsync
		BSP_LCD_ClearStringLine( 9 );
		BSP_LCD_DisplayStringAtLine( 9, (uint8_t*)pcTempCoString );
	}
}

void vMainNewClientCallback( char *pcRemoteIP )
{
	/* Print remote IP */
	BSP_LCD_SetTextColor( LCD_COLOR_WHITE );
	BSP_LCD_FillRect( 250, 10, BSP_LCD_GetXSize()-250, BSP_LCD_GetFont()->Height );
	BSP_LCD_SetTextColor( LCD_COLOR_GREEN );
	BSP_LCD_DisplayStringAt( 250, 10, (uint8_t*)pcRemoteIP, LEFT_MODE);
	BSP_LCD_SetTextColor( LCD_COLOR_BLACK );
}

void vMainConnectionCloseCallback( void )
{
	/* clear string */
	BSP_LCD_SetTextColor( LCD_COLOR_WHITE );
	BSP_LCD_FillRect( 250, 10, BSP_LCD_GetXSize()-250, BSP_LCD_GetFont()->Height );
	BSP_LCD_SetTextColor( LCD_COLOR_BLACK );
}

/* USER CODE END 4 */

void Error_Handler(void)
{
  while(1)
  {
  }
}

/************************ (C) COPYRIGHT STMicroelectronics *****END OF FILE****/
